# STM32H573 register map
File version: 1.7
CPU: CM33 r0p0, little endian, MPU, FPU, 4 interrupt priority bits
Registers are 32-bit, read-write, reset 0x0 unless marked. A register's access mark holds for its fields unless they carry their own. Offsets are from the block's base; [hi:lo] are bit positions; {n}, {i} and the like mark numbered series; 'fields as' and 'values as' point back to an identical list.

## TIM1 (part 1 of 2) — Advanced-control timers
Base 0x40012C00
Same registers: SEC_TIM1 0x50012C00
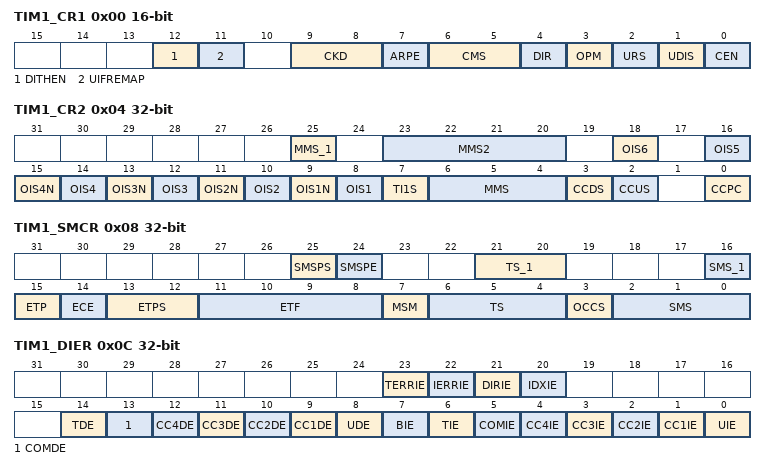
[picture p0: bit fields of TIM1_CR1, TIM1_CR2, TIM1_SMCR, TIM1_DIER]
0x00 TIM1_CR1 16-bit — TIM1 control register 1
  [12] DITHEN — Dithering enable Note: The DITHEN bit can only be modified when CEN bit is reset.
    0=Dithering disabled; 1=Dithering enabled
  [11] UIFREMAP — UIF status bit remapping
    0=No remapping. UIF status bit is not copied to TIMx_CNT register bit 31.; 1=Remapping enabled. UIF status bit is copied to TIMx_CNT register bit 31.
  [9:8] CKD — Clock division This bit-field indicates the division ratio between the timer clock (tim_ker_ck) frequency and the dead-time and sampling clock (t sub DTS /sub )used by the dead-time generators and the digital filters (tim_etr_in, tim_tix),
    0=t sub DTS /sub =t sub tim_ker_ck /sub; 1=t sub DTS /sub =2*t sub tim_ker_ck /sub; 2=t sub DTS /sub =4*t sub tim_ker_ck /sub; 3=Reserved, do not program this value
  [7] ARPE — Auto-reload preload enable
    0=TIMx_ARR register is not buffered; 1=TIMx_ARR register is buffered
  [6:5] CMS — Center-aligned mode selection Note: It is not allowed to switch from edge-aligned mode to center-aligned mode as long as the counter is enabled (CEN=1)
    0=Edge-aligned mode. The counter counts up or down depending on the direction bit (DIR).; 1=Center-aligned mode 1. The counter counts up and down alternatively. Output compare interrupt flags of channels configured in output (CCxS=00 in TIMx_CCMRx register) are set only when the counter is counting down.; 2=Center-aligned mode 2. The counter counts up and down alternatively. Output compare interrupt flags of channels configured in output (CCxS=00 in TIMx_CCMRx register) are set only when the counter is counting up.; 3=Center-aligned mode 3. The counter counts up and down alternatively. Output compare interrupt flags of channels configured in output (CCxS=00 in TIMx_CCMRx register) are set both when the counter is counting up or down.
  [4] DIR — Direction Note: This bit is read only when the timer is configured in Center-aligned mode or Encoder mode.
    0=Counter used as upcounter; 1=Counter used as downcounter
  [3] OPM — One-pulse mode
    0=Counter is not stopped at update event; 1=Counter stops counting at the next update event (clearing the bit CEN)
  [2] URS — Update request source This bit is set and cleared by software to select the UEV event sources. Counter overflow/underflow Setting the UG bit Update generation through the slave mode controller
    0=Any of the following events generate an update interrupt or DMA request if enabled. These events can be:; 1=Only counter overflow/underflow generates an update interrupt or DMA request if enabled
  [1] UDIS — Update disable This bit is set and cleared by software to enable/disable UEV event generation. Counter overflow/underflow Setting the UG bit Update generation through the slave mode controller Buffered registers are then loaded with their preload values.
    0=UEV enabled. The Update (UEV) event is generated by one of the following events:; 1=UEV disabled. The Update event is not generated, shadow registers keep their value (ARR, PSC, CCRx). However the counter and the prescaler are reinitialized if the UG bit is set or if a hardware reset is received from the slave mode controller.
  [0] CEN — Counter enable Note: External clock, gated mode and encoder mode can work only if the CEN bit has been previously set by software. However trigger mode can set the CEN bit automatically by hardware.
    0=Counter disabled; 1=Counter enabled
0x04 TIM1_CR2 — TIM1 control register 2
  [25] MMS_1 — MMS[3]
  [23:20] MMS2 — Master mode selection 2 These bits allow the information to be sent to ADC for synchronization (tim_trgo2) to be selected. The combination is as follows: Note: The clock of the slave timer or ADC must be enabled prior to receive events from the master timer, and must not be changed on-the-fly while triggers are received from the master timer.
    0=Reset the UG bit from the TIMx_EGR register is used as trigger output (tim_trgo2). If the reset is generated by the trigger input (slave mode controller configured in reset mode), the signal on tim_trgo2 is delayed compared to the actual reset.; 1=Enable the Counter Enable signal CNT_EN is used as trigger output (tim_trgo2). It is useful to start several timers at the same time or to control a window in which a slave timer is enabled. The Counter Enable signal is generated by a logic AND between the CEN control bit and the trigger input when configured in Gated mode. When the Counter Enable signal is controlled by the trigger input, there is a delay on tim_trgo2, except if the Master/Slave mode is selected (see the MSM bit description in TIMx_SMCR register).; 2=Update the update event is selected as trigger output (tim_trgo2). For instance, a master timer can then be used as a prescaler for a slave timer.; 3=Compare pulse the trigger output sends a positive pulse when the CC1IF flag is to be set (even if it was already high), as soon as a capture or compare match occurs (tim_trgo2); {v}=Compare tim_oc{v-3}refc signal is used as trigger output (tim_trgo2) (v=4..9); 10=Compare Pulse tim_oc4refc rising or falling edges generate pulses on tim_trgo2; 11=Compare pulse tim_oc6refc rising or falling edges generate pulses on tim_trgo2; 12=Compare pulse tim_oc4refc or tim_oc6refc rising edges generate pulses on tim_trgo2; 13=Compare pulse tim_oc4refc rising or tim_oc6refc falling edges generate pulses on tim_trgo2; 14=Compare pulse tim_oc5refc or tim_oc6refc rising edges generate pulses on tim_trgo2; 15=Compare pulse tim_oc5refc rising or tim_oc6refc falling edges generate pulses on tim_trgo2
  [18] OIS6 — Output idle state 6 (tim_oc6 output) Refer to OIS1 bit
  [16] OIS5 — Output idle state 5 (tim_oc5 output) Refer to OIS1 bit
  [15] OIS4N — Output idle state 4 (tim_oc4n output) Refer to OIS1N bit
  [14] OIS4 — Output idle state 4 (tim_oc4 output) Refer to OIS1 bit
  [13] OIS3N — Output idle state 3 (tim_oc3n output) Refer to OIS1N bit
  [12] OIS3 — Output idle state 3 (tim_oc3n output) Refer to OIS1 bit
  [11] OIS2N — Output idle state 2 (tim_oc2n output) Refer to OIS1N bit
  [10] OIS2 — Output idle state 2 (tim_oc2 output) Refer to OIS1 bit
  [9] OIS1N — Output idle state 1 (tim_oc1n output) Note: This bit can not be modified as long as LOCK level 1, 2 or 3 has been programmed (LOCK bits in TIMx_BDTR register).
    0=tim_oc1n=0 after a dead-time when MOE=0; 1=tim_oc1n=1 after a dead-time when MOE=0
  [8] OIS1 — Output idle state 1 (tim_oc1 output) Note: This bit can not be modified as long as LOCK level 1, 2 or 3 has been programmed (LOCK bits in TIMx_BDTR register).
    0=tim_oc1=0 (after a dead-time) when MOE=0; 1=tim_oc1=1 (after a dead-time) when MOE=0
  [7] TI1S — tim_ti1 selection
    0=The tim_ti1_in[15..0] multiplexer output is connected to tim_ti1 input; 1=tim_ti1_in[15..0], tim_ti2_in[15..0] and tim_ti3_in[15..0] multiplexers outputs are XORed and connected to the tim_ti1 input
  [6:4] MMS — MMS[2:0]: Master mode selection These bits select the information to be sent in master mode to slave timers for synchronization (tim_trgo). The combination is as follows: Other codes reserved Note: The clock of the slave timer or ADC must be enabled prior to receive events from the master timer, and must not be changed on-the-fly while triggers are received from the master timer.
    0=Reset the UG bit from the TIMx_EGR register is used as trigger output (tim_trgo). If the reset is generated by the trigger input (slave mode controller configured in reset mode) then the signal on tim_trgo is delayed compared to the actual reset.; 1=Enable the Counter Enable signal CNT_EN is used as trigger output (tim_trgo). It is useful to start several timers at the same time or to control a window in which a slave timer is enable. The Counter Enable signal is generated by a logic AND between CEN control bit and the trigger input when configured in gated mode. When the Counter Enable signal is controlled by the trigger input, there is a delay on tim_trgo, except if the master/slave mode is selected (see the MSM bit description in TIMx_SMCR register).; 2=Update The update event is selected as trigger output (tim_trgo). For instance a master timer can then be used as a prescaler for a slave timer.; 3=Compare Pulse The trigger output send a positive pulse when the CC1IF flag is to be set (even if it was already high), as soon as a capture or a compare match occurred. (tim_trgo).; {v}=Compare tim_oc{v-3}refc signal is used as trigger output (tim_trgo) (v=4..7)
  [3] CCDS — Capture/compare DMA selection
    0=CCx DMA request sent when CCx event occurs; 1=CCx DMA requests sent when update event occurs
  [2] CCUS — Capture/compare control update selection Note: This bit acts only on channels that have a complementary output.
    0=When capture/compare control bits are preloaded (CCPC=1), they are updated by setting the COMG bit only; 1=When capture/compare control bits are preloaded (CCPC=1), they are updated by setting the COMG bit or when an rising edge occurs on tim_trgi
  [0] CCPC — Capture/compare preloaded control Note: This bit acts only on channels that have a complementary output.
    0=CCxE, CCxNE and OCxM bits are not preloaded; 1=CCxE, CCxNE and OCxM bits are preloaded, after having been written, they are updated only when a commutation event (COM) occurs (COMG bit set or rising edge detected on tim_trgi, depending on the CCUS bit)
0x08 TIM1_SMCR — TIM1 slave mode control register
  [25] SMSPS — SMS preload source This bit selects whether the events that triggers the SMS[3:0] bitfield transfer from preload to active
    0=The transfer is triggered by the Timer's Update event; 1=The transfer is triggered by the Index event
  [24] SMSPE — SMS preload enable This bit selects whether the SMS[3:0] bitfield is preloaded
    0=SMS[3:0] bitfield is not preloaded; 1=SMS[3:0] preload is enabled
  [21:20] TS_1 — Trigger selection This bit-field selects the trigger input to be used to synchronize the counter. Others: Reserved See for product specific implementation details. Note: These bits must be changed only when they are not used (e.g. when SMS=000) to avoid wrong edge detections at the transition.
    {v}=Internal trigger {v} (tim_itr{v}) (v=0..3)
  [16] SMS_1 — Slave mode selection When external signals are selected the active edge of the trigger signal (tim_trgi) is linked to the polarity selected on the external input (see Input Control register and Control Register description. Note: The gated mode must not be used if tim_ti1f_ed is selected as the trigger input (TS=00100). Indeed, tim_ti1f_ed outputs 1 pulse for each transition on tim_ti1f, whereas the gated mode checks the level of the trigger signal. Note: The clock of the slave peripherals (timer, ADC, ...) receiving the tim_trgo signal must be enabled prior to receive events from the master timer, and the clock frequency (prescaler) must not be changed on-the-fly while triggers are received from the master timer.
    0=Slave mode disabled - if CEN = '1 then the prescaler is clocked directly by the internal clock; 1=Encoder mode 1 - Counter counts up/down on tim_ti1fp1 edge depending on tim_ti2fp2 level
  [15] ETP — External trigger polarity This bit selects whether tim_etr_in or tim_etr_in is used for trigger operations
    0=tim_etr_in is non-inverted, active at high level or rising edge; 1=tim_etr_in is inverted, active at low level or falling edge
  [14] ECE — External clock enable This bit enables External clock mode 2. Note: Setting the ECE bit has the same effect as selecting external clock mode 1 with tim_trgi connected to tim_etrf (SMS=111 and TS=00111). It is possible to simultaneously use external clock mode 2 with the following slave modes: reset mode, gated mode and trigger mode. Nevertheless, tim_trgi must not be connected to tim_etrf in this case (TS bits must not be 00111). Note: If external clock mode 1 and external clock mode 2 are enabled at the same time, the external clock input is tim_etrf.
    0=External clock mode 2 disabled; 1=External clock mode 2 enabled. The counter is clocked by any active edge on the tim_etrf signal.
  [13:12] ETPS — External trigger prescaler External trigger signal tim_etrp frequency must be at most 1/4 of TIMxCLK frequency. A prescaler can be enabled to reduce tim_etrp frequency. It is useful when inputting fast external clocks on tim_etr_in.
    0=Prescaler OFF; 1=tim_etr_in frequency divided by 2; 2=tim_etr_in frequency divided by 4; 3=tim_etr_in frequency divided by 8
  [11:8] ETF — External trigger filter This bit-field then defines the frequency used to sample tim_etrp signal and the length of the digital filter applied to tim_etrp. The digital filter is made of an event counter in which N consecutive events are needed to validate a transition on the output:
    0=No filter, sampling is done at f sub DTS /sub; 1=f sub SAMPLING /sub =f sub tim_ker_ck /sub , N=2; 2=f sub SAMPLING /sub =f sub tim_ker_ck /sub , N=4; 3=f sub SAMPLING /sub =f sub tim_ker_ck /sub , N=8; 4=f sub SAMPLING /sub =f sub DTS /sub /2, N=6; 5=f sub SAMPLING /sub =f sub DTS /sub /2, N=8; 6=f sub SAMPLING /sub =f sub DTS /sub /4, N=6; 7=f sub SAMPLING /sub =f sub DTS /sub /4, N=8; 8=f sub SAMPLING /sub =f sub DTS /sub /8, N=6; 9=f sub SAMPLING /sub =f sub DTS /sub /8, N=8; 10=f sub SAMPLING /sub =f sub DTS /sub /16, N=5; 11=f sub SAMPLING /sub =f sub DTS /sub /16, N=6; 12=f sub SAMPLING /sub =f sub DTS /sub /16, N=8; 13=f sub SAMPLING /sub =f sub DTS /sub /32, N=5; 14=f sub SAMPLING /sub =f sub DTS /sub /32, N=6; 15=f sub SAMPLING /sub =f sub DTS /sub /32, N=8
  [7] MSM — Master/slave mode
    0=No action; 1=The effect of an event on the trigger input (tim_trgi) is delayed to allow a perfect synchronization between the current timer and its slaves (through tim_trgo). It is useful if we want to synchronize several timers on a single external event.
  [6:4] TS — TS[2:0]: Trigger selection This bitfield is combined with TS[4:3] bits. This bit-field selects the trigger input to be used to synchronize the counter. Others: Reserved See Table 605: TIMx internal trigger connection for more details on tim_itrx meaning for each Timer. Note: These bits must be changed only when they are not used (e.g. when SMS=000) to avoid wrong edge detections at the transition.
    {v}=Internal Trigger {v} (tim_itr{v}) (v=0..3); 4=tim_ti1 Edge Detector (tim_ti1f_ed); 5=Filtered Timer Input 1 (tim_ti1fp1); 6=Filtered Timer Input 2 (tim_ti2fp2); 7=External Trigger input (tim_etrf)
  [3] OCCS — OCREF clear selection This bit is used to select the OCREF clear source.
    0=tim_ocref_clr_int is connected to the tim_ocref_clr input; 1=tim_ocref_clr_int is connected to tim_etrf
  [2:0] SMS — SMS[2:0]: Slave mode selection When external signals are selected the active edge of the trigger signal (tim_trgi) is linked to the polarity selected on the external input (see Input Control register and Control Register description. Note: The gated mode must not be used if tim_ti1f_ed is selected as the trigger input (TS=00100). Indeed, tim_ti1f_ed outputs 1 pulse for each transition on TI1F, whereas the gated mode checks the level of the trigger signal. Note: The clock of the slave peripherals (timer, ADC, ...) receiving the tim_trgo or the tim_trgo2 signals must be enabled prior to receive events from the master timer, and the clock frequency (prescaler) must not be changed on-the-fly while triggers are received from the master timer.
    0=Slave mode disabled if CEN = '1' then the prescaler is clocked directly by the internal clock; 1=Quadrature encoder mode 1, x2 mode- Counter counts up/down on tim_ti1fp1 edge depending on tim_ti2fp2 level; 2=Quadrature encoder mode 2, x2 mode Counter counts up/down on tim_ti2fp2 edge depending on tim_ti1fp1 level; 3=Quadrature encoder mode 3, x4 mode Counter counts up/down on both tim_ti1fp1 and tim_ti2fp2 edges depending on the level of the other input; 4=Reset Mode Rising edge of the selected trigger input (tim_trgi) reinitializes the counter and generates an update of the registers; 5=Gated Mode The counter clock is enabled when the trigger input (tim_trgi) is high. The counter stops (but is not reset) as soon as the trigger becomes low. Both start and stop of the counter are controlled.; 6=Trigger Mode The counter starts at a rising edge of the trigger tim_trgi (but it is not reset). Only the start of the counter is controlled.; 7=External Clock Mode 1 Rising edges of the selected trigger (tim_trgi) clock the counter
0x0C TIM1_DIER — TIM1 DMA/interrupt enable register
  [23] TERRIE — Transition error interrupt enable
    0=Transition error interrupt disabled; 1=Transition error interrupt enabled
  [22] IERRIE — Index error interrupt enable
    0=Index error interrupt disabled; 1=Index error interrupt enabled
  [21] DIRIE — Direction change interrupt enable
    0=Direction Change interrupt disabled; 1=Direction Change interrupt enabled
  [20] IDXIE — Index interrupt enable
    0=Index interrupt disabled; 1=Index Change interrupt enabled
  [14] TDE — Trigger DMA request enable
    0=Trigger DMA request disabled; 1=Trigger DMA request enabled
  [13] COMDE — COM DMA request enable
    0=COM DMA request disabled; 1=COM DMA request enabled
  [n+8] CC{n}DE (n=1..4) — Capture/compare {n} DMA request enable
    0=CC{n} DMA request disabled; 1=CC{n} DMA request enabled
  [8] UDE — Update DMA request enable
    0=Update DMA request disabled; 1=Update DMA request enabled
  [7] BIE — Break interrupt enable
    0=Break interrupt disabled; 1=Break interrupt enabled
  [6] TIE — Trigger interrupt enable
    0=Trigger interrupt disabled; 1=Trigger interrupt enabled
  [5] COMIE — COM interrupt enable
    0=COM interrupt disabled; 1=COM interrupt enabled
  [n] CC{n}IE (n=1..4) — Capture/compare {n} interrupt enable
    0=CC{n} interrupt disabled; 1=CC{n} interrupt enabled
  [0] UIE — Update interrupt enable
    0=Update interrupt disabled; 1=Update interrupt enabled
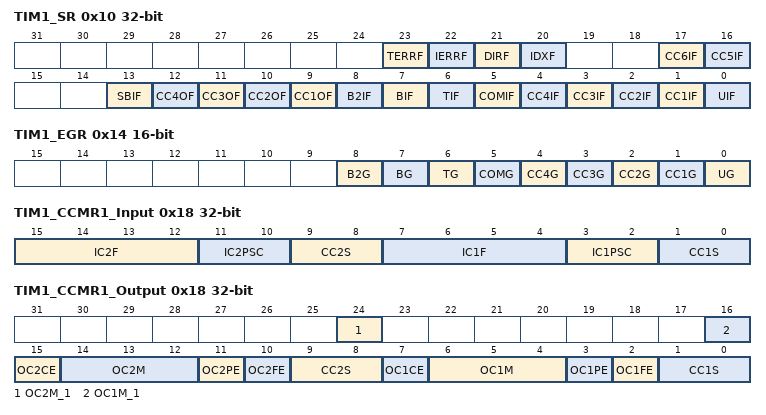
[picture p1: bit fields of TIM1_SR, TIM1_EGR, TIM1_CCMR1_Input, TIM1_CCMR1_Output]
0x10 TIM1_SR — TIM1 status register
  [23] TERRF — Transition error interrupt flag This flag is set by hardware when a transition error is detected in encoder mode. It is cleared by software by writing it to '0'.
    0=No encoder transition error has been detected; 1=An encoder transition error has been detected
  [22] IERRF — Index error interrupt flag This flag is set by hardware when an index error is detected. It is cleared by software by writing it to '0'.
    0=No index error has been detected; 1=An index error has been detected
  [21] DIRF — Direction change interrupt flag This flag is set by hardware when the direction changes in encoder mode (DIR bit value in TIMx_CR is changing). It is cleared by software by writing it to '0'.
    0=No direction change; 1=Direction change
  [20] IDXF — Index interrupt flag This flag is set by hardware when an index event is detected. It is cleared by software by writing it to '0'.
    0=No index event occurred; 1=An index event has occurred
  [17] CC6IF — Compare 6 interrupt flag Refer to CC1IF description Note: Channel 6 can only be configured as output.
  [16] CC5IF — Compare 5 interrupt flag Refer to CC1IF description Note: Channel 5 can only be configured as output.
  [13] SBIF — System break interrupt flag This flag is set by hardware as soon as the system break input goes active. It can be cleared by software if the system break input is not active. This flag must be reset to re-start PWM operation.
    0=No break event occurred; 1=An active level has been detected on the system break input. An interrupt is generated if BIE=1 in the TIMx_DIER register.
  [12] CC4OF — Capture/compare 4 overcapture flag Refer to CC1OF description
  [11] CC3OF — Capture/compare 3 overcapture flag Refer to CC1OF description
  [10] CC2OF — Capture/compare 2 overcapture flag Refer to CC1OF description
  [9] CC1OF — Capture/compare 1 overcapture flag This flag is set by hardware only when the corresponding channel is configured in input capture mode. It is cleared by software by writing it to '0'.
    0=No overcapture has been detected; 1=The counter value has been captured in TIMx_CCR1 register while CC1IF flag was already set
  [8] B2IF — Break 2 interrupt flag This flag is set by hardware as soon as the break 2 input goes active. It can be cleared by software if the break 2 input is not active.
    0=No break event occurred; 1=An active level has been detected on the break 2 input. An interrupt is generated if BIE=1 in the TIMx_DIER register.
  [7] BIF — Break interrupt flag This flag is set by hardware as soon as the break input goes active. It can be cleared by software if the break input is not active.
    0=No break event occurred; 1=An active level has been detected on the break input. An interrupt is generated if BIE=1 in the TIMx_DIER register.
  [6] TIF — Trigger interrupt flag This flag is set by hardware on the TRG trigger event (active edge detected on tim_trgi input when the slave mode controller is enabled in all modes but gated mode. It is set when the counter starts or stops when gated mode is selected. It is cleared by software.
    0=No trigger event occurred; 1=Trigger interrupt pending
  [5] COMIF — COM interrupt flag This flag is set by hardware on COM event (when capture/compare Control bits CCxE, CCxNE, OCxM have been updated). It is cleared by software.
    0=No COM event occurred; 1=COM interrupt pending
  [4] CC4IF — Capture/compare 4 interrupt flag Refer to CC1IF description
  [3] CC3IF — Capture/compare 3 interrupt flag Refer to CC1IF description
  [2] CC2IF — Capture/compare 2 interrupt flag Refer to CC1IF description
  [1] CC1IF — Capture/compare 1 interrupt flag This flag is set by hardware. It is cleared by software (input capture or output compare mode) or by reading the TIMx_CCR1 register (input capture mode only). If channel CC1 is configured as output: this flag is set when the content of the counter TIMx_CNT matches the content of the TIMx_CCR1 register. When the content of TIMx_CCR1 is greater than the content of TIMx_ARR, the CC1IF bit goes high on the counter overflow (in up-counting and up/down-counting modes) or underflow (in downcounting mode). There are 3 possible options for flag setting in center-aligned mode, refer to the CMS bits in the TIMx_CR1 register for the full description. If channel CC1 is configured as input: this bit is set when counter value has been captured in TIMx_CCR1 register (an edge has been detected on IC1, as per the edge sensitivity defined with the CC1P and CC1NP bits setting, in TIMx_CCER).
    0=No compare match / No input capture occurred; 1=A compare match or an input capture occurred
  [0] UIF — Update interrupt flag This bit is set by hardware on an update event. It is cleared by software. At overflow or underflow regarding the repetition counter value (update if repetition counter = 0) and if the UDIS=0 in the TIMx_CR1 register. When CNT is reinitialized by software using the UG bit in TIMx_EGR register, if URS=0 and UDIS=0 in the TIMx_CR1 register. When CNT is reinitialized by a trigger event (refer to Section 65.6.3: TIM1 slave mode control register (TIM1_SMCR)), if URS=0 and UDIS=0 in the TIMx_CR1 register.
    0=No update occurred; 1=Update interrupt pending. This bit is set by hardware when the registers are updated:
0x14 TIM1_EGR 16-bit wo — TIM1 event generation register
  [8] B2G — Break 2 generation This bit is set by software in order to generate an event, it is automatically cleared by hardware.
    0=No action; 1=A break 2 event is generated. MOE bit is cleared and B2IF flag is set. Related interrupt can occur if enabled.
  [7] BG — Break generation This bit is set by software in order to generate an event, it is automatically cleared by hardware.
    0=No action; 1=A break event is generated. MOE bit is cleared and BIF flag is set. Related interrupt or DMA transfer can occur if enabled.
  [6] TG — Trigger generation This bit is set by software in order to generate an event, it is automatically cleared by hardware.
    0=No action; 1=The TIF flag is set in TIMx_SR register. Related interrupt or DMA transfer can occur if enabled.
  [5] COMG — Capture/compare control update generation This bit can be set by software, it is automatically cleared by hardware Note: This bit acts only on channels having a complementary output.
    0=No action; 1=When CCPC bit is set, it allows to update CCxE, CCxNE and OCxM bits
  [4] CC4G — Capture/compare 4 generation Refer to CC1G description
  [3] CC3G — Capture/compare 3 generation Refer to CC1G description
  [2] CC2G — Capture/compare 2 generation Refer to CC1G description
  [1] CC1G — Capture/compare 1 generation This bit is set by software in order to generate an event, it is automatically cleared by hardware. If channel CC1 is configured as output: CC1IF flag is set, Corresponding interrupt or DMA request is sent if enabled. If channel CC1 is configured as input: The current value of the counter is captured in TIMx_CCR1 register. The CC1IF flag is set, the corresponding interrupt or DMA request is sent if enabled. The CC1OF flag is set if the CC1IF flag was already high.
    0=No action; 1=A capture/compare event is generated on channel 1:
  [0] UG — Update generation This bit can be set by software, it is automatically cleared by hardware.
    0=No action; 1=Reinitialize the counter and generates an update of the registers. Note that the prescaler counter is cleared too (anyway the prescaler ratio is not affected). The counter is cleared if the center-aligned mode is selected or if DIR=0 (upcounting), else it takes the auto-reload value (TIMx_ARR) if DIR=1 (downcounting).
0x18 TIM1_CCMR1_Input — TIM1 capture/compare mode register 1 [alternate]
  [15:12] IC2F — Input capture 2 filter
  [11:10] IC2PSC — Input capture 2 prescaler
  [9:8] CC2S — Capture/compare 2 selection This bit-field defines the direction of the channel (input/output) as well as the used input. Note: CC2S bits are writable only when the channel is OFF (CC2E = '0' in TIMx_CCER).
    0=CC2 channel is configured as output; 1=CC2 channel is configured as input, tim_ic2 is mapped on tim_ti2; 2=CC2 channel is configured as input, tim_ic2 is mapped on tim_ti1; 3=CC2 channel is configured as input, tim_ic2 is mapped on tim_trc. This mode is working only if an internal trigger input is selected through TS bit (TIMx_SMCR register)
  [7:4] IC1F — Input capture 1 filter This bit-field defines the frequency used to sample tim_ti1 input and the length of the digital filter applied to tim_ti1. The digital filter is made of an event counter in which N consecutive events are needed to validate a transition on the output:
    values as TIM1_SMCR.ETF
  [3:2] IC1PSC — Input capture 1 prescaler This bit-field defines the ratio of the prescaler acting on CC1 input (tim_ic1). The prescaler is reset as soon as CC1E='0' (TIMx_CCER register).
    0=no prescaler, capture is done each time an edge is detected on the capture input; 1=capture is done once every 2 events; 2=capture is done once every 4 events; 3=capture is done once every 8 events
  [1:0] CC1S — Capture/compare 1 Selection This bit-field defines the direction of the channel (input/output) as well as the used input. Note: CC1S bits are writable only when the channel is OFF (CC1E = '0' in TIMx_CCER).
    0=CC1 channel is configured as output; 1=CC1 channel is configured as input, tim_ic1 is mapped on tim_ti1; 2=CC1 channel is configured as input, tim_ic1 is mapped on tim_ti2; 3=CC1 channel is configured as input, tim_ic1 is mapped on tim_trc. This mode is working only if an internal trigger input is selected through TS bit (TIMx_SMCR register)
0x18 TIM1_CCMR1_Output (alternate view of TIM1_CCMR1_Input) — TIM1 capture/compare mode register 1 [alternate]
  [24] OC2M_1 — OC2M[3]
  [16] OC1M_1 — OC1M[3]
  [15] OC2CE — Output compare 2 clear enable
  [14:12] OC2M — OC2M[2:0]: Output compare 2 mode
  [11] OC2PE — Output compare 2 preload enable
  [10] OC2FE — Output compare 2 fast enable
  [9:8] CC2S — Capture/compare 2 selection This bit-field defines the direction of the channel (input/output) as well as the used input. Note: CC2S bits are writable only when the channel is OFF (CC2E = '0' in TIMx_CCER).
    0=CC2 channel is configured as output; 1=CC2 channel is configured as input, tim_ic2 is mapped on tim_ti2; 2=CC2 channel is configured as input, tim_ic2 is mapped on tim_ti1; 3=CC2 channel is configured as input, tim_ic2 is mapped on tim_trc. This mode is working only if an internal trigger input is selected through the TS bit (TIMx_SMCR register)
  [7] OC1CE — Output compare 1 clear enable
    0=tim_oc1ref is not affected by the tim_ocref_clr_int signal; 1=tim_oc1ref is cleared as soon as a High level is detected on tim_ocref_clr_int signal (tim_ocref_clr input or tim_etrf input)
  [6:4] OC1M — OC1M[2:0]: Output compare 1 mode These bits define the behavior of the output reference signal tim_oc1ref from which tim_oc1 and tim_oc1n are derived. tim_oc1ref is active high whereas tim_oc1 and tim_oc1n active level depends on CC1P and CC1NP bits. Note: These bits can not be modified as long as LOCK level 3 has been programmed (LOCK bits in TIMx_BDTR register) and CC1S='00' (the channel is configured in output). Note: In PWM mode, the OCREF level changes only when the result of the comparison changes or when the output compare mode switches from 'frozen' mode to 'PWM' mode. Note: On channels having a complementary output, this bit field is preloaded. If the CCPC bit is set in the TIMx_CR2 register then the OC1M active bits take the new value from the preloaded bits only when a COM event is generated.
    0=Frozen The comparison between the output compare register TIMx_CCR1 and the counter TIMx_CNT has no effect on the outputs.(this mode is used to generate a timing base); 1=Set channel 1 to active level on match. tim_oc1ref signal is forced high when the counter TIMx_CNT matches the capture/compare register 1 (TIMx_CCR1).; 2=Set channel 1 to inactive level on match. tim_oc1ref signal is forced low when the counter TIMx_CNT matches the capture/compare register 1 (TIMx_CCR1).; 3=Toggle tim_oc1ref toggles when TIMx_CNT=TIMx_CCR1; 4=Force inactive level tim_oc1ref is forced low; 5=Force active level tim_oc1ref is forced high; 6=PWM mode 1 In upcounting, channel 1 is active as long as TIMx_CNT TIMx_CCR1 else inactive. In downcounting, channel 1 is inactive (tim_oc1ref='0') as long as TIMx_CNT TIMx_CCR1 else active (tim_oc1ref='1').; 7=PWM mode 2 In upcounting, channel 1 is inactive as long as TIMx_CNT TIMx_CCR1 else active. In downcounting, channel 1 is active as long as TIMx_CNT TIMx_CCR1 else inactive.
  [3] OC1PE — Output compare 1 preload enable Note: These bits can not be modified as long as LOCK level 3 has been programmed (LOCK bits in TIMx_BDTR register) and CC1S='00' (the channel is configured in output).
    0=Preload register on TIMx_CCR1 disabled. TIMx_CCR1 can be written at anytime, the new value is taken in account immediately.; 1=Preload register on TIMx_CCR1 enabled. Read/Write operations access the preload register. TIMx_CCR1 preload value is loaded in the active register at each update event.
  [2] OC1FE — Output compare 1 fast enable This bit decreases the latency between a trigger event and a transition on the timer output. It must be used in one-pulse mode (OPM bit set in TIMx_CR1 register), to have the output pulse starting as soon as possible after the starting trigger.
    0=CC1 behaves normally depending on counter and CCR1 values even when the trigger is ON. The minimum delay to activate CC1 output when an edge occurs on the trigger input is 5 clock cycles.; 1=An active edge on the trigger input acts like a compare match on CC1 output. Then, OC is set to the compare level independently from the result of the comparison. Delay to sample the trigger input and to activate CC1 output is reduced to 3 clock cycles. OCFE acts only if the channel is configured in PWM1 or PWM2 mode.
  [1:0] CC1S — Capture/compare 1 selection This bit-field defines the direction of the channel (input/output) as well as the used input. Note: CC1S bits are writable only when the channel is OFF (CC1E = '0' in TIMx_CCER).
    values as TIM1_CCMR1_Input.CC1S
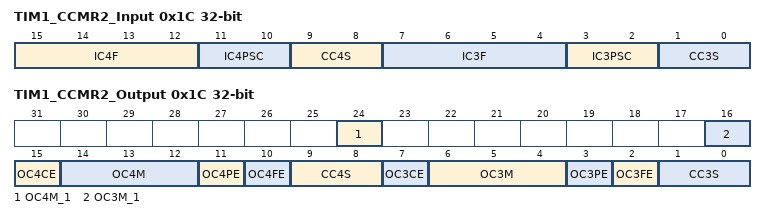
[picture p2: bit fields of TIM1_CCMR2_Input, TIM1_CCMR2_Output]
0x1C TIM1_CCMR2_Input — TIM1 capture/compare mode register 2 [alternate]
  [15:12] IC4F — Input capture 4 filter
  [11:10] IC4PSC — Input capture 4 prescaler
  [9:8] CC4S — Capture/compare 4 selection This bit-field defines the direction of the channel (input/output) as well as the used input. Note: CC4S bits are writable only when the channel is OFF (CC4E = '0' in TIMx_CCER).
    0=CC4 channel is configured as output; 1=CC4 channel is configured as input, tim_ic4 is mapped on tim_ti4; 2=CC4 channel is configured as input, tim_ic4 is mapped on tim_ti3; 3=CC4 channel is configured as input, tim_ic4 is mapped on tim_trc. This mode is working only if an internal trigger input is selected through TS bit (TIMx_SMCR register)
  [7:4] IC3F — Input capture 3 filter
  [3:2] IC3PSC — Input capture 3 prescaler
  [1:0] CC3S — Capture/compare 3 selection This bit-field defines the direction of the channel (input/output) as well as the used input. Note: CC3S bits are writable only when the channel is OFF (CC3E = '0' in TIMx_CCER).
    0=CC3 channel is configured as output; 1=CC3 channel is configured as input, tim_ic3 is mapped on tim_ti3; 2=CC3 channel is configured as input, tim_ic3 is mapped on tim_ti4; 3=CC3 channel is configured as input, tim_ic3 is mapped on tim_trc. This mode is working only if an internal trigger input is selected through TS bit (TIMx_SMCR register)
0x1C TIM1_CCMR2_Output (alternate view of TIM1_CCMR2_Input) — TIM1 capture/compare mode register 2 [alternate]
  [24] OC4M_1 — OC4M[3]
  [16] OC3M_1 — OC3M[3]
  [15] OC4CE — Output compare 4 clear enable
  [14:12] OC4M — OC4M[2:0]: Output compare 4 mode Refer to OC3M[3:0] bit description
  [11] OC4PE — Output compare 4 preload enable
  [10] OC4FE — Output compare 4 fast enable
  [9:8] CC4S — Capture/compare 4 selection This bit-field defines the direction of the channel (input/output) as well as the used input. Note: CC4S bits are writable only when the channel is OFF (CC4E = '0' in TIMx_CCER).
    values as TIM1_CCMR2_Input.CC4S
  [7] OC3CE — Output compare 3 clear enable
  [6:4] OC3M — OC3M[2:0]: Output compare 3 mode These bits define the behavior of the output reference signal tim_oc3ref from which tim_oc3 and tim_oc3n are derived. tim_oc3ref is active high whereas tim_oc3 and tim_oc3n active level depends on CC3P and CC3NP bits. Note: These bits can not be modified as long as LOCK level 3 has been programmed (LOCK bits in TIMx_BDTR register) and CC1S='00' (the channel is configured in output). Note: In PWM mode, the OCREF level changes only when the result of the comparison changes or when the output compare mode switches from 'frozen' mode to 'PWM' mode. On channels having a complementary output, this bit field is preloaded. If the CCPC bit is set in the TIMx_CR2 register then the OC3M active bits take the new value from the preloaded bits only when a COM event is generated.
    0=Frozen The comparison between the output compare register TIMx_CCR3 and the counter TIMx_CNT has no effect on the outputs.(this mode is used to generate a timing base); 1=Set channel 3 to active level on match. tim_oc3ref signal is forced high when the counter TIMx_CNT matches the capture/compare register 3 (TIMx_CCR3).; 2=Set channel 3 to inactive level on match. tim_oc3ref signal is forced low when the counter TIMx_CNT matches the capture/compare register 3 (TIMx_CCR3).; 3=Toggle tim_oc3ref toggles when TIMx_CNT=TIMx_CCR3; 4=Force inactive level tim_oc3ref is forced low; 5=Force active level tim_oc3ref is forced high; 6=PWM mode 1 In upcounting, channel 3 is active as long as TIMx_CNT TIMx_CCR3 else inactive. In downcounting, channel 3 is inactive (tim_oc3ref='0') as long as TIMx_CNT TIMx_CCR3 else active (tim_oc3ref='1').; 7=PWM mode 2 In upcounting, channel 3 is inactive as long as TIMx_CNT TIMx_CCR3 else active. In downcounting, channel 3 is active as long as TIMx_CNT TIMx_CCR3 else inactive.
  [3] OC3PE — Output compare 3 preload enable
  [2] OC3FE — Output compare 3 fast enable
  [1:0] CC3S — Capture/compare 3 selection This bit-field defines the direction of the channel (input/output) as well as the used input. Note: CC3S bits are writable only when the channel is OFF (CC3E = '0' in TIMx_CCER).
    values as TIM1_CCMR2_Input.CC3S

## TIM8 (part 1 of 2) — Advanced-control timers
Base 0x40013400
Same registers: SEC_TIM8 0x50013400
Registers as TIM1 (with TIM1 read as TIM8); these are added or differ:
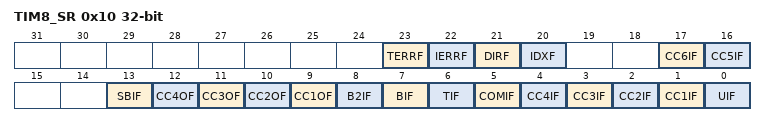
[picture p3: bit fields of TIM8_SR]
0x10 TIM8_SR — TIM8 status register
  fields as TIM1.TIM1_SR
